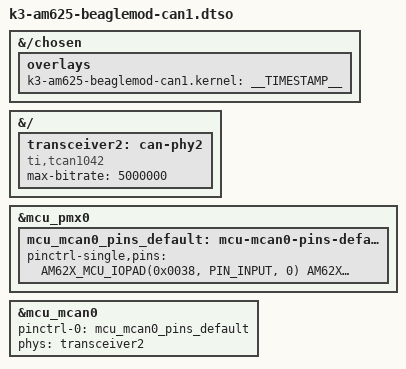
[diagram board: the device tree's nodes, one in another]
// SPDX-License-Identifier: GPL-2.0
/*
 * Copyright (C) 2022 Texas Instruments Incorporated - https://www.ti.com/
 */

/dts-v1/;
/plugin/;

#include "k3-pinctrl.h"

/*
 * Helper to show loaded overlays under: /proc/device-tree/chosen/overlays/
 */
&{/chosen} {
	overlays {
		k3-am625-beaglemod-can1.kernel = __TIMESTAMP__;
	};
};

&{/} {
	transceiver2: can-phy2 {
		compatible = "ti,tcan1042";
		#phy-cells = <0>;
		max-bitrate = <5000000>;
	};
};

&mcu_pmx0 {
	mcu_mcan0_pins_default: mcu-mcan0-pins-default {
		pinctrl-single,pins = <
			AM62X_MCU_IOPAD(0x0038, PIN_INPUT, 0) /* (B3) MCU_MCAN0_RX */
			AM62X_MCU_IOPAD(0x0034, PIN_OUTPUT, 0) /* (D6) MCU_MCAN0_TX */
		>;
	};
};

&mcu_mcan0 {
	pinctrl-names = "default";
	pinctrl-0 = <&mcu_mcan0_pins_default>;
	phys = <&transceiver2>;
	status = "okay";
};
